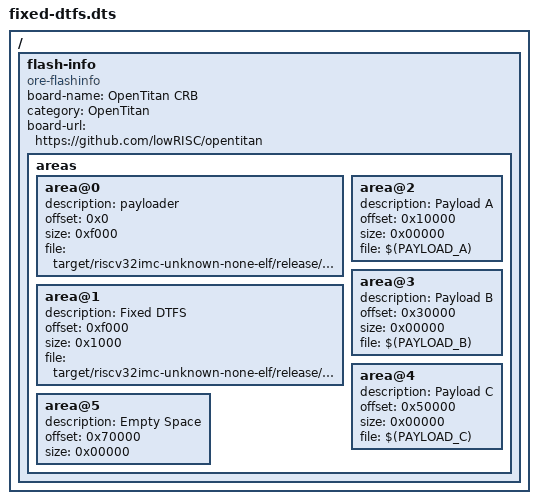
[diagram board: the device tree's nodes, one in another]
/dts-v1/;

/ {
    #address-cells = <1>;
    #size-cells = <1>;

    flash-info {
        compatible = "ore-flashinfo";
        board-name = "OpenTitan CRB";
        category = "OpenTitan";
        board-url = "https://github.com/lowRISC/opentitan";
        areas {
            area@0 {
                description = "payloader";
                offset = <0x0>;
                size = <0xf000>; // 64KiB - 4 KiB
                file = "target/riscv32imc-unknown-none-elf/release/flash.bin";
            };
            area@1 {
                description = "Fixed DTFS";
                offset = <0xf000>;
                size = <0x1000>; // 4KiB
                file = "target/riscv32imc-unknown-none-elf/release/fixed-dtfs.dtb";
            };
            area@2 {
                description = "Payload A";
                offset = <0x10000>;
                size = <0x00000>; // 0x20000 later128 KiB
                file = "$(PAYLOAD_A)";
            };
            area@3 {
                description = "Payload B";
                offset = <0x30000>;
                size = <0x00000>; 
                file = "$(PAYLOAD_B)";
            };
            area@4 {
                description = "Payload C";
                offset = <0x50000>;
                size = <0x00000>; 
                file = "$(PAYLOAD_C)";
            };
            area@5 {
                description = "Empty Space";
                offset = <0x70000>;
                size = <0x00000>;  // 0x10000 later
            };
        };
    };
};
